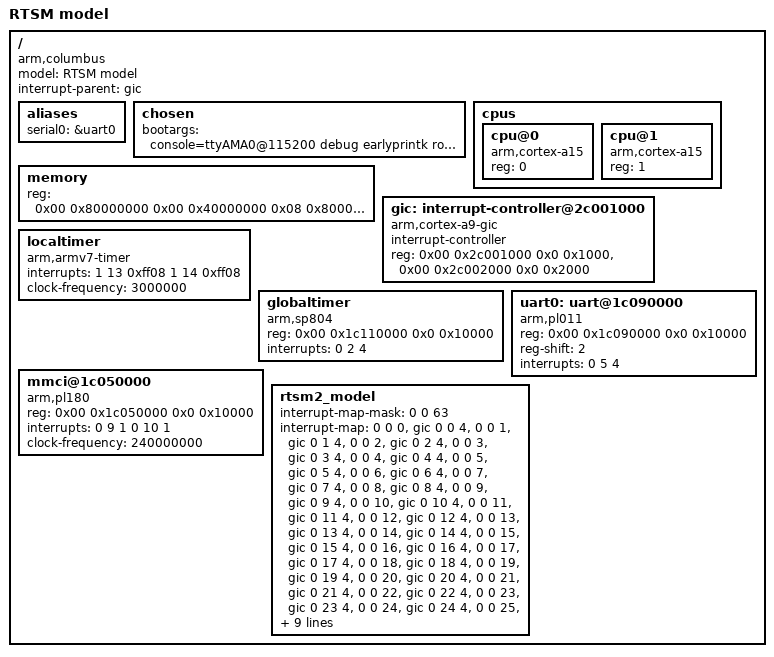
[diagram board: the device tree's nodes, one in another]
// ARM Ltd. Columbus Compute Subsystem

/dts-v1/;

/ {
	model = "RTSM model";
	compatible = "arm,columbus";
	interrupt-parent = <&gic>;
	#address-cells = <2>;
	#size-cells = <2>;

	aliases {
		serial0 = &uart0;
	};
	
	chosen {
		bootargs = "console=ttyAMA0@115200 debug earlyprintk root=/dev/mmcblk0 rootwait";
	};

	cpus {
		#address-cells = <1>;
		#size-cells = <0>;

		cpu@0 {
			device_type = "cpu";
			compatible = "arm,cortex-a15";
			reg = <0>;
		};

		cpu@1 {
			device_type = "cpu";
			compatible = "arm,cortex-a15";
			reg = <1>;
		};
	};

	memory {
		device_type = "memory";
		reg = <0x00 0x80000000 0x00 0x40000000
		       0x08 0x80000000 0x07 0x80000000
		       0x88 0x00000000 0x78 0x00000000>;
	};

	gic: interrupt-controller@2c001000 {
		compatible = "arm,cortex-a9-gic";
		interrupt-controller;
		#interrupt-cells = <3>;
		#address-cells = <0>;
		reg = <0x00 0x2c001000 0x0 0x1000>,
		      <0x00 0x2c002000 0x0 0x2000>;
	};

	localtimer {
		compatible = "arm,armv7-timer";
		interrupts = <1 13 0xff08  1 14 0xff08>;
		clock-frequency = <3000000>;
	};

	globaltimer {
		compatible = "arm,sp804", "arm,primecell";
		reg = <0x00 0x1c110000 0x0 0x10000>;
		interrupts = <0 2 4>;
	};

	uart0: uart@1c090000 {
		compatible = "arm,pl011", "arm,primecell";
		reg = <0x00 0x1c090000 0x0 0x10000>;
		reg-shift = <2>;
		interrupts = <0 5 4>;
	};

	mmci@1c050000 {
		compatible = "arm,pl180", "arm,primecell";
		reg = <0x00 0x1c050000 0x0 0x10000>;
		interrupts = <0  9 1 
			      0 10 1>;
		clock-frequency = <240000000>;
	};

	rtsm2_model {
		ranges = <0 0 0x0 0x08000000 0x0 0x04000000>,
		         <1 0 0x0 0x14000000 0x0 0x04000000>,
			 <2 0 0x0 0x18000000 0x0 0x04000000>,
			 <3 0 0x0 0x1c000000 0x0 0x04000000>,
			 <4 0 0x0 0x0c000000 0x0 0x04000000>,
			 <5 0 0x0 0x10000000 0x0 0x04000000>;

		interrupt-map-mask = <0 0 63>;
		interrupt-map = <0 0  0 &gic 0  0 4>,
			        <0 0  1 &gic 0  1 4>,
			        <0 0  2 &gic 0  2 4>,
			        <0 0  3 &gic 0  3 4>,
			        <0 0  4 &gic 0  4 4>,
			        <0 0  5 &gic 0  5 4>,
			        <0 0  6 &gic 0  6 4>,
			        <0 0  7 &gic 0  7 4>,
			        <0 0  8 &gic 0  8 4>,
			        <0 0  9 &gic 0  9 4>,
			        <0 0 10 &gic 0 10 4>,
			        <0 0 11 &gic 0 11 4>,
			        <0 0 12 &gic 0 12 4>,
			        <0 0 13 &gic 0 13 4>,
			        <0 0 14 &gic 0 14 4>,
			        <0 0 15 &gic 0 15 4>,
			        <0 0 16 &gic 0 16 4>,
			        <0 0 17 &gic 0 17 4>,
			        <0 0 18 &gic 0 18 4>,
			        <0 0 19 &gic 0 19 4>,
			        <0 0 20 &gic 0 20 4>,
			        <0 0 21 &gic 0 21 4>,
			        <0 0 22 &gic 0 22 4>,
			        <0 0 23 &gic 0 23 4>,
			        <0 0 24 &gic 0 24 4>,
			        <0 0 25 &gic 0 25 4>,
			        <0 0 26 &gic 0 26 4>,
			        <0 0 27 &gic 0 27 4>,
			        <0 0 28 &gic 0 28 4>,
			        <0 0 29 &gic 0 29 4>,
			        <0 0 30 &gic 0 30 4>,
			        <0 0 31 &gic 0 31 4>,
			        <0 0 32 &gic 0 32 4>,
			        <0 0 33 &gic 0 33 4>,
			        <0 0 34 &gic 0 34 4>,
			        <0 0 35 &gic 0 35 4>,
			        <0 0 36 &gic 0 36 4>,
			        <0 0 37 &gic 0 37 4>,
			        <0 0 38 &gic 0 38 4>,
			        <0 0 39 &gic 0 39 4>,
			        <0 0 40 &gic 0 40 4>,
			        <0 0 41 &gic 0 41 4>,
			        <0 0 42 &gic 0 42 4>;
	};

};
